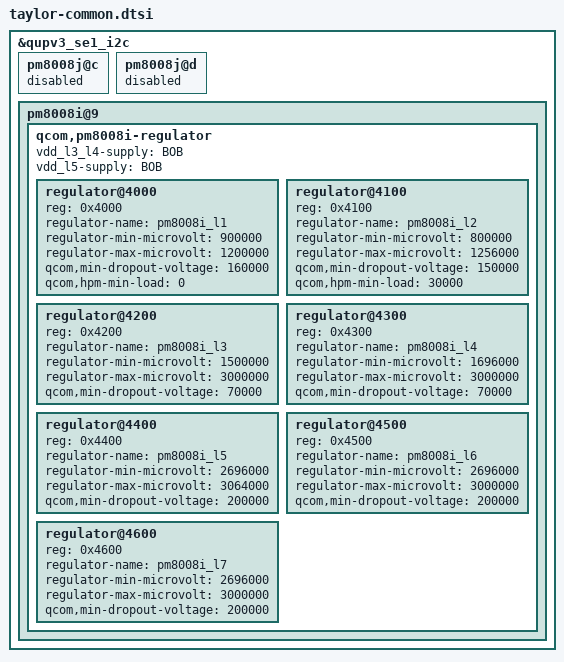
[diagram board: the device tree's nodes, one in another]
&qupv3_se1_i2c {
	status = "ok";
	pm8008j@c {
		status = "disabled";
	};

	pm8008j@d {
		status = "disabled";
	};

	pm8008i@9 {

		qcom,pm8008i-regulator {
			vdd_l3_l4-supply = <&BOB>;
			vdd_l5-supply = <&BOB>;

			regulator@4000 {
				reg = <0x4000>;
				regulator-name = "pm8008i_l1";
				regulator-min-microvolt = <900000>;
				regulator-max-microvolt = <1200000>;
				qcom,min-dropout-voltage = <160000>;
				qcom,hpm-min-load = <0>;
			};

			regulator@4100 {
				reg = <0x4100>;
				regulator-name = "pm8008i_l2";
				regulator-min-microvolt = <800000>;
				regulator-max-microvolt = <1256000>;
				qcom,min-dropout-voltage = <150000>;
				qcom,hpm-min-load = <30000>;
			};
			regulator@4200 {
				reg = <0x4200>;
				regulator-name = "pm8008i_l3";
				regulator-min-microvolt = <1500000>;
				regulator-max-microvolt = <3000000>;
				qcom,min-dropout-voltage = <70000>;
			};

			regulator@4300 {
				reg = <0x4300>;
				regulator-name = "pm8008i_l4";
				regulator-min-microvolt = <1696000>;
				regulator-max-microvolt = <3000000>;
				qcom,min-dropout-voltage = <70000>;
			};

			regulator@4400 {
				reg = <0x4400>;
				regulator-name = "pm8008i_l5";
				regulator-min-microvolt = <2696000>;
				regulator-max-microvolt = <3064000>;
				qcom,min-dropout-voltage = <200000>;
			};

			regulator@4500 {
				reg = <0x4500>;
				regulator-name = "pm8008i_l6";
				regulator-min-microvolt = <2696000>;
				regulator-max-microvolt = <3000000>;
				qcom,min-dropout-voltage = <200000>;
			};

			regulator@4600 {
				reg = <0x4600>;
				regulator-name = "pm8008i_l7";
				regulator-min-microvolt = <2696000>;
				regulator-max-microvolt = <3000000>;
				qcom,min-dropout-voltage = <200000>;
			};
		};
	};
};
